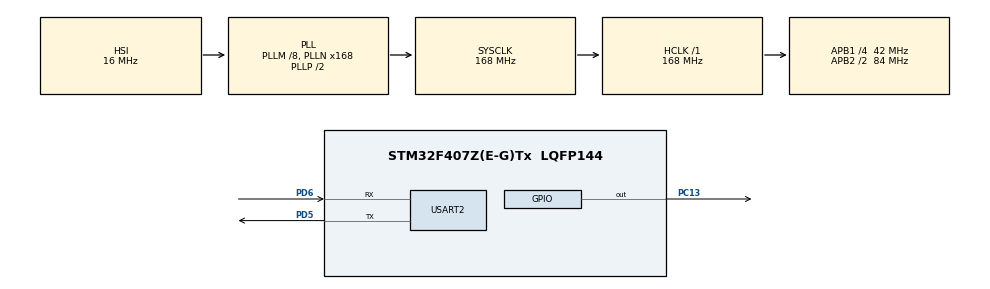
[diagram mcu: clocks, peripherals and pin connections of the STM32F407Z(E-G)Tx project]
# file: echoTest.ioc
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Dma.Request0=USART2_RX
Dma.USART2_RX.0.Direction=DMA_PERIPH_TO_MEMORY
Dma.USART2_RX.0.FIFOMode=DMA_FIFOMODE_DISABLE
Dma.USART2_RX.0.Instance=DMA1_Stream5
Dma.USART2_RX.0.MemDataAlignment=DMA_MDATAALIGN_BYTE
Dma.USART2_RX.0.MemInc=DMA_MINC_ENABLE
Dma.USART2_RX.0.Mode=DMA_NORMAL
Dma.USART2_RX.0.PeriphDataAlignment=DMA_PDATAALIGN_BYTE
Dma.USART2_RX.0.PeriphInc=DMA_PINC_DISABLE
Dma.USART2_RX.0.Priority=DMA_PRIORITY_LOW
Mcu.Family=STM32F4
Mcu.Name=STM32F407Z(E-G)Tx
Mcu.Package=LQFP144
NVIC.DMA1_Stream5_IRQn=true\:0\:0\:false\:false\:true\:false\:true
NVIC.PriorityGroup=NVIC_PRIORITYGROUP_4
PC13-ANTI_TAMP.GPIO_ModeDefaultOutputPP=GPIO_MODE_OUTPUT_PP
PC13-ANTI_TAMP.GPIO_PuPd=GPIO_NOPULL
PC13-ANTI_TAMP.Signal=GPIO_Output
PD5.Mode=Asynchronous
PD5.Signal=USART2_TX
PD6.Mode=Asynchronous
PD6.Signal=USART2_RX
ProjectManager.HeapSize=0x200
ProjectManager.StackSize=0x400
ProjectManager.TargetToolchain=Makefile
RCC.48MHZClocksFreq_Value=84000000
RCC.AHBFreq_Value=168000000
RCC.APB1CLKDivider=RCC_HCLK_DIV4
RCC.APB1Freq_Value=42000000
RCC.APB1TimFreq_Value=84000000
RCC.APB2CLKDivider=RCC_HCLK_DIV2
RCC.APB2Freq_Value=84000000
RCC.APB2TimFreq_Value=168000000
RCC.CortexFreq_Value=168000000
RCC.HCLKFreq_Value=168000000
RCC.HSE_VALUE=25000000
RCC.HSI_VALUE=16000000
RCC.LSE_VALUE=32768
RCC.PLLM=8
RCC.PLLN=168
RCC.SYSCLKFreq_VALUE=168000000
RCC.SYSCLKSource=RCC_SYSCLKSOURCE_PLLCLK
RCC.VCOOutputFreq_Value=336000000
USART2.VirtualMode=VM_ASYNC
board=custom

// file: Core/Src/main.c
/* USER CODE BEGIN Header */
/**
  ******************************************************************************
  * @file           : main.c
  * @brief          : Main program body
  ******************************************************************************
  * @attention
  *
  * <h2><center>&copy; Copyright (c) 2021 STMicroelectronics.
  * All rights reserved.</center></h2>
  *
  * This software component is licensed by ST under BSD 3-Clause license,
  * the "License"; You may not use this file except in compliance with the
  * License. You may obtain a copy of the License at:
  *                        opensource.org/licenses/BSD-3-Clause
  *
  ******************************************************************************
  */
/* USER CODE END Header */
#include "main.h"

/* USER CODE BEGIN PD */
#define DATA_SIZE  12
/* USER CODE END PD */

UART_HandleTypeDef huart2;
DMA_HandleTypeDef hdma_usart2_rx;

/* USER CODE BEGIN PV */
char buffRX[DATA_SIZE] = {0};
char buffTX[] = "Hello World\r\n";

/* USER CODE END PV */

void SystemClock_Config(void);
static void MX_GPIO_Init(void);
static void MX_DMA_Init(void);
static void MX_USART2_UART_Init(void);

/* USER CODE BEGIN 0 */
void HAL_UART_RxCpltCallback(UART_HandleTypeDef *huart)
{
    // Send whatever we received to the same UART peripheral
    HAL_UART_Transmit(huart, buffRX, sizeof(buffRX), HAL_MAX_DELAY);

    // Tell DMA to receive more data in the same UART
    HAL_UART_Receive_DMA(huart, buffRX, DATA_SIZE);
}
/* USER CODE END 0 */

int main(void)
{

  /* MCU Configuration--------------------------------------------------------*/

  /* Reset of all peripherals, Initializes the Flash interface and the Systick. */
  HAL_Init();

  /* Configure the system clock */
  SystemClock_Config();

  /* Initialize all configured peripherals */
  MX_GPIO_Init();
  MX_DMA_Init();
  MX_USART2_UART_Init();

  /* Infinite loop */
  /* USER CODE BEGIN WHILE */

  // Receive data from UART (DATA_SIZE bytes) and store in buffer.
  // HAL_UART_RxCpltCallback will be called when DATA_SIZE bytes have been received.
  HAL_UART_Receive_DMA (&huart2, buffRX, DATA_SIZE);

  while (1)
  {
    // Blinking LED
    HAL_GPIO_TogglePin(GPIOC, GPIO_PIN_13);
    HAL_Delay(1000);

    /*
    TODO : Transmit DMA does not work as expected. It only send one byte of data and then stops.
    Does circular mode solve it?
    */
    //HAL_UART_Transmit_DMA(&huart2, buffTX, sizeof(buffTX)); //Non-blocking mode with DMA

    HAL_UART_Transmit(&huart2, buffTX, sizeof(buffTX), HAL_MAX_DELAY); // Blocking

    /* USER CODE END WHILE */

  }
}

void SystemClock_Config(void)
{
  RCC_OscInitTypeDef RCC_OscInitStruct = {0};
  RCC_ClkInitTypeDef RCC_ClkInitStruct = {0};

  /** Configure the main internal regulator output voltage
  */
  __HAL_RCC_PWR_CLK_ENABLE();
  __HAL_PWR_VOLTAGESCALING_CONFIG(PWR_REGULATOR_VOLTAGE_SCALE1);
  /** Initializes the RCC Oscillators according to the specified parameters
  * in the RCC_OscInitTypeDef structure.
  */
  RCC_OscInitStruct.OscillatorType = RCC_OSCILLATORTYPE_HSI;
  RCC_OscInitStruct.HSIState = RCC_HSI_ON;
  RCC_OscInitStruct.HSICalibrationValue = RCC_HSICALIBRATION_DEFAULT;
  RCC_OscInitStruct.PLL.PLLState = RCC_PLL_ON;
  RCC_OscInitStruct.PLL.PLLSource = RCC_PLLSOURCE_HSI;
  RCC_OscInitStruct.PLL.PLLM = 8;
  RCC_OscInitStruct.PLL.PLLN = 168;
  RCC_OscInitStruct.PLL.PLLP = RCC_PLLP_DIV2;
  RCC_OscInitStruct.PLL.PLLQ = 4;
  if (HAL_RCC_OscConfig(&RCC_OscInitStruct) != HAL_OK)
  {
    Error_Handler();
  }
  /** Initializes the CPU, AHB and APB buses clocks
  */
  RCC_ClkInitStruct.ClockType = RCC_CLOCKTYPE_HCLK|RCC_CLOCKTYPE_SYSCLK
                              |RCC_CLOCKTYPE_PCLK1|RCC_CLOCKTYPE_PCLK2;
  RCC_ClkInitStruct.SYSCLKSource = RCC_SYSCLKSOURCE_PLLCLK;
  RCC_ClkInitStruct.AHBCLKDivider = RCC_SYSCLK_DIV1;
  RCC_ClkInitStruct.APB1CLKDivider = RCC_HCLK_DIV4;
  RCC_ClkInitStruct.APB2CLKDivider = RCC_HCLK_DIV2;

  if (HAL_RCC_ClockConfig(&RCC_ClkInitStruct, FLASH_LATENCY_5) != HAL_OK)
  {
    Error_Handler();
  }
}

static void MX_USART2_UART_Init(void)
{

  huart2.Instance = USART2;
  huart2.Init.BaudRate = 115200;
  huart2.Init.WordLength = UART_WORDLENGTH_8B;
  huart2.Init.StopBits = UART_STOPBITS_1;
  huart2.Init.Parity = UART_PARITY_NONE;
  huart2.Init.Mode = UART_MODE_TX_RX;
  huart2.Init.HwFlowCtl = UART_HWCONTROL_NONE;
  huart2.Init.OverSampling = UART_OVERSAMPLING_16;
  if (HAL_UART_Init(&huart2) != HAL_OK)
  {
    Error_Handler();
  }

}

static void MX_DMA_Init(void)
{

  /* DMA controller clock enable */
  __HAL_RCC_DMA1_CLK_ENABLE();

  /* DMA interrupt init */
  /* DMA1_Stream5_IRQn interrupt configuration */
  HAL_NVIC_SetPriority(DMA1_Stream5_IRQn, 0, 0);
  HAL_NVIC_EnableIRQ(DMA1_Stream5_IRQn);

}

static void MX_GPIO_Init(void)
{
  GPIO_InitTypeDef GPIO_InitStruct = {0};

  /* GPIO Ports Clock Enable */
  __HAL_RCC_GPIOC_CLK_ENABLE();
  __HAL_RCC_GPIOD_CLK_ENABLE();

  /*Configure GPIO pin Output Level */
  HAL_GPIO_WritePin(GPIOC, GPIO_PIN_13, GPIO_PIN_RESET);

  /*Configure GPIO pin : PC13 */
  GPIO_InitStruct.Pin = GPIO_PIN_13;
  GPIO_InitStruct.Mode = GPIO_MODE_OUTPUT_PP;
  GPIO_InitStruct.Pull = GPIO_NOPULL;
  GPIO_InitStruct.Speed = GPIO_SPEED_FREQ_LOW;
  HAL_GPIO_Init(GPIOC, &GPIO_InitStruct);

}

void Error_Handler(void)
{
  __disable_irq();
  while (1)
  {
  }
}

/************************ (C) COPYRIGHT STMicroelectronics *****END OF FILE****/
